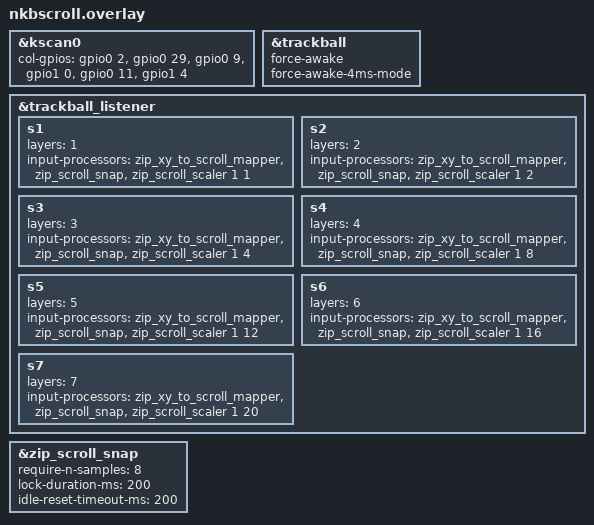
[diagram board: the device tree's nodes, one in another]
/* Scroll test: standalone. Hold key0 -> scroll layer, trackball scrolls with
   axis-snap (kot149/zmk-scroll-snap). Cursor on base layer. */
#include "nice_kb.dtsi"
#include <scroll-snap.dtsi>
#include <input/processors.dtsi>

&kscan0 {
    col-gpios
        = <&gpio0  2 (GPIO_ACTIVE_HIGH | GPIO_PULL_DOWN)>
        , <&gpio0 29 (GPIO_ACTIVE_HIGH | GPIO_PULL_DOWN)>
        , <&gpio0  9 (GPIO_ACTIVE_HIGH | GPIO_PULL_DOWN)>
        , <&gpio1  0 (GPIO_ACTIVE_HIGH | GPIO_PULL_DOWN)>
        , <&gpio0 11 (GPIO_ACTIVE_HIGH | GPIO_PULL_DOWN)>
        , <&gpio1  4 (GPIO_ACTIVE_HIGH | GPIO_PULL_DOWN)>
        ;
};

&trackball {
    force-awake;
    force-awake-4ms-mode;
};

/* 3 snap-scroll speed presets on 3 layers (scaler after snap so snap
   thresholds see raw values). fast=1/1, med=1/2, slow=1/4. */
&trackball_listener {
    /* 7 speed presets. layer N -> ratio (scaler after snap). */
    s1 { layers = <1>; input-processors = <&zip_xy_to_scroll_mapper &zip_scroll_snap &zip_scroll_scaler 1 1>;  };  /* 1/1  */
    s2 { layers = <2>; input-processors = <&zip_xy_to_scroll_mapper &zip_scroll_snap &zip_scroll_scaler 1 2>;  };  /* 1/2  */
    s3 { layers = <3>; input-processors = <&zip_xy_to_scroll_mapper &zip_scroll_snap &zip_scroll_scaler 1 4>;  };  /* 1/4  */
    s4 { layers = <4>; input-processors = <&zip_xy_to_scroll_mapper &zip_scroll_snap &zip_scroll_scaler 1 8>;  };  /* 1/8  */
    s5 { layers = <5>; input-processors = <&zip_xy_to_scroll_mapper &zip_scroll_snap &zip_scroll_scaler 1 12>; };  /* 1/12 */
    s6 { layers = <6>; input-processors = <&zip_xy_to_scroll_mapper &zip_scroll_snap &zip_scroll_scaler 1 16>; };  /* 1/16 */
    s7 { layers = <7>; input-processors = <&zip_xy_to_scroll_mapper &zip_scroll_snap &zip_scroll_scaler 1 20>; };  /* 1/20 */
};

/* optional snap tuning (defaults are fine to start) */
&zip_scroll_snap {
    require-n-samples = <8>;
    lock-duration-ms = <200>;
    idle-reset-timeout-ms = <200>;
};
